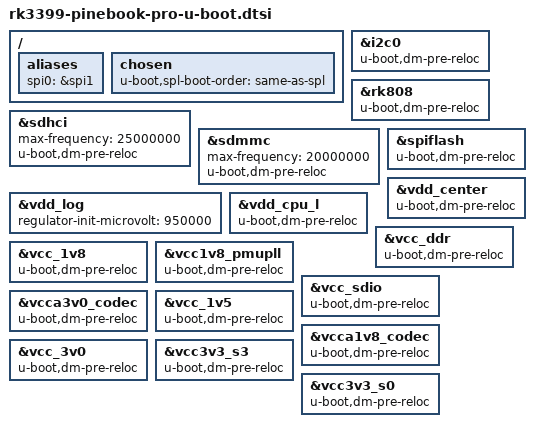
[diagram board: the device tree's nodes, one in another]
// SPDX-License-Identifier: GPL-2.0+
/*
 * Copyright (C) 2019 Peter Robinson <pbrobinson at gmail.com>
 */

#include "rk3399-u-boot.dtsi"
#include "rk3399-sdram-lpddr4-100.dtsi"

/ {
	aliases {
		spi0 = &spi1;
	};

	chosen {
		u-boot,spl-boot-order = "same-as-spl", &sdhci, &sdmmc;
	};
};

&i2c0 {
	u-boot,dm-pre-reloc;
};

&rk808 {
	u-boot,dm-pre-reloc;
};

&sdhci {
	max-frequency = <25000000>;
	u-boot,dm-pre-reloc;
};

&sdmmc {
	max-frequency = <20000000>;
	u-boot,dm-pre-reloc;
};

&spiflash {
	u-boot,dm-pre-reloc;
};

&vdd_log {
	regulator-init-microvolt = <950000>;
};

&vdd_center {
	u-boot,dm-pre-reloc;
};

&vdd_cpu_l {
	u-boot,dm-pre-reloc;
};

&vcc_ddr {
	u-boot,dm-pre-reloc;
};

&vcc_1v8 {
	u-boot,dm-pre-reloc;
};

&vcc1v8_pmupll {
	u-boot,dm-pre-reloc;
};

&vcc_sdio {
	u-boot,dm-pre-reloc;
};

&vcca3v0_codec {
	u-boot,dm-pre-reloc;
};

&vcc_1v5 {
	u-boot,dm-pre-reloc;
};

&vcca1v8_codec {
	u-boot,dm-pre-reloc;
};

&vcc_3v0 {
	u-boot,dm-pre-reloc;
};

&vcc3v3_s3 {
	u-boot,dm-pre-reloc;
};

&vcc3v3_s0 {
	u-boot,dm-pre-reloc;
};
